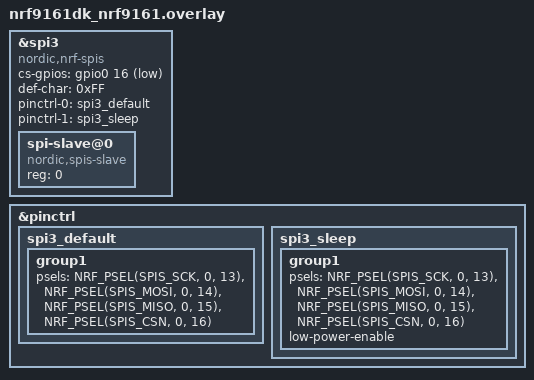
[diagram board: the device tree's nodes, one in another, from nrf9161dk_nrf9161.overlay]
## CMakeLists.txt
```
cmake_minimum_required(VERSION 3.20.0)
find_package(Zephyr REQUIRED HINTS $ENV{ZEPHYR_BASE})

project(SPI-slave)

target_sources(app PRIVATE src/main.c)
```

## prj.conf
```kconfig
# Enable logging
CONFIG_LOG=y
CONFIG_LOG_DEFAULT_LEVEL=3

# Enable SPI driver
CONFIG_SPI=y
CONFIG_SPI_SLAVE=y        # <-- Required for using SPIS peripheral

# Enable main thread
CONFIG_MAIN_STACK_SIZE=2048

# Optional: enable console output via UART/RTT
CONFIG_SERIAL=y
CONFIG_UART_CONSOLE=y
CONFIG_USE_SEGGER_RTT=n
CONFIG_PRINTK=y
CONFIG_STDOUT_CONSOLE=y
```

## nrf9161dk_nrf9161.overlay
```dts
&spi3 {
    compatible = "nordic,nrf-spis";
    status = "okay";

    cs-gpios = <&gpio0 16 GPIO_ACTIVE_LOW>;
    def-char = <0xFF>;
    pinctrl-0 = <&spi3_default>;
    pinctrl-1 = <&spi3_sleep>;
    pinctrl-names = "default", "sleep";

    spi-slave@0 {                           /* ← fixed: added @0 */
        compatible = "nordic,spis-slave";
        reg = <0>;
        status = "okay";
    };            
};

&pinctrl {
    spi3_default: spi3_default {
        group1 {
            psels = <NRF_PSEL(SPIS_SCK, 0, 13)>,
                    <NRF_PSEL(SPIS_MOSI, 0, 14)>,
                    <NRF_PSEL(SPIS_MISO, 0, 15)>,
                    <NRF_PSEL(SPIS_CSN, 0, 16)>;
        };
    };

    spi3_sleep: spi3_sleep {
        group1 {
            psels = <NRF_PSEL(SPIS_SCK, 0, 13)>,
                    <NRF_PSEL(SPIS_MOSI, 0, 14)>,
                    <NRF_PSEL(SPIS_MISO, 0, 15)>,
                    <NRF_PSEL(SPIS_CSN, 0, 16)>;
            low-power-enable;
        };
    };
};
```

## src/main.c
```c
#include <zephyr/kernel.h>
#include <zephyr/device.h>
#include <zephyr/drivers/spi.h>
#include <zephyr/logging/log.h>

LOG_MODULE_REGISTER(spi_slave_demo, LOG_LEVEL_INF);

/* SPI slave node from device tree */
#define SPI_SLAVE_NODE DT_NODELABEL(spi3)

static const struct device *spis_dev = DEVICE_DT_GET(SPI_SLAVE_NODE);

/* TX and RX buffers */
static uint8_t tx_buf[4] = {0x11, 0x22, 0x33, 0x44};
static uint8_t rx_buf[4] = {0};

/* SPI buffer structures */
static struct spi_buf tx_spi_buf = {
    .buf = tx_buf,
    .len = sizeof(tx_buf)
};

static struct spi_buf rx_spi_buf = {
    .buf = rx_buf,
    .len = sizeof(rx_buf)
};

static const struct spi_buf_set tx_set = {
    .buffers = &tx_spi_buf,
    .count = 1
};

static const struct spi_buf_set rx_set = {
    .buffers = &rx_spi_buf,
    .count = 1
};

/* SPI configuration for NCS v3.1.1 */
/* Mode 0: CPOL=0, CPHA=0, MSB first, slave mode */
static const struct spi_config spi_cfg = {
    .operation = SPI_OP_MODE_SLAVE | SPI_TRANSFER_MSB | SPI_WORD_SET(8), // Mode 0
    .frequency = 1000000,  // ignored in slave, required field
    .slave = 0,
    .cs = NULL,            // Chip select handled externally
};

void main(void)
{
    if (!device_is_ready(spis_dev)) {
        LOG_ERR("SPI device not ready");
        return;
    }  

    LOG_INF("nRF9161 SPI Slave Ready");

    while (1) {
        //k_msleep(5);
        int ret = spi_transceive(spis_dev, NULL, &tx_set, &rx_set);
        LOG_INF("Received: %02X %02X %02X %02X",
                rx_buf[0], rx_buf[1], rx_buf[2], rx_buf[3]);

        for (int i = 0; i < 4; i++) {
                tx_buf[i] = rx_buf[i] + 1;
            }

        if (ret == 0) {
            LOG_INF("Received: %02X %02X %02X %02X",
                rx_buf[0], rx_buf[1], rx_buf[2], rx_buf[3]);

            /* Update TX buffer for next transfer */
            for (int i = 0; i < 4; i++) {
                tx_buf[i] = rx_buf[i] + 1;
            }
        } else if (ret == -EIO) {
            /* No master activity yet; optional to ignore */
            // LOG_DBG("No master activity yet");
        } else {
            continue;
            //LOG_ERR("SPI transceive failed: %d", ret);
        }

        k_msleep(10000); /* reduce CPU load */
    }
}
```
